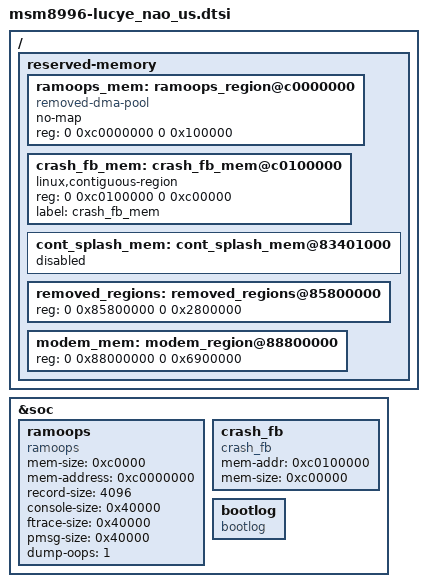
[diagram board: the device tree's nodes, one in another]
/* Copyright (c) 2015, The Linux Foundation. All rights reserved.
 * Copyright (c) 2017, The LineageOS Project. All rights reserved.
 *
 * This program is free software; you can redistribute it and/or modify
 * it under the terms of the GNU General Public License version 2 and
 * only version 2 as published by the Free Software Foundation.
 *
 * This program is distributed in the hope that it will be useful,
 * but WITHOUT ANY WARRANTY; without even the implied warranty of
 * MERCHANTABILITY or FITNESS FOR A PARTICULAR PURPOSE.  See the
 * GNU General Public License for more details.
 */

/* Generic Qualcomm tree */
 #include "../../qcom/msm8996pro-v1.1.dtsi"
 #include "../../qcom/msm-pmi8996.dtsi"
 #include "../../qcom/msm8996-mtp.dtsi"

/* Device specific tree */
#include "msm8996-lucye_nao_us-panel.dtsi"
#include "../msm8996-lucye-touch-sic-sw49408.dtsi"
#include "msm8996-lucye_nao_us-usb.dtsi"

/ {
	reserved-memory {
		ramoops_mem: ramoops_region@c0000000 {
			compatible = "removed-dma-pool";
			no-map;
			reg = <0 0xc0000000 0 0x100000>;
		};

		crash_fb_mem: crash_fb_mem@c0100000 {
			linux,contiguous-region;
			reg = <0 0xc0100000 0 0xc00000>;
			label = "crash_fb_mem";
		};

		cont_splash_mem: cont_splash_mem@83401000 {
			status = "disabled";
		};

		/delete-node/ dfps_data_mem@83400000;

		removed_regions: removed_regions@85800000 {
			reg = <0 0x85800000 0 0x2800000>;
		};

		modem_mem: modem_region@88800000 {
			reg = <0 0x88000000 0 0x6900000>;
		};
	};
};

&soc {
  ramoops {
		compatible = "ramoops";
		mem-size = <0xc0000>;
		mem-address = <0xc0000000>;
		record-size = <4096>;
		console-size = <0x40000>;
		ftrace-size = <0x40000>;
		pmsg-size = <0x40000>;
		dump-oops = <1>;
	};

	crash_fb {
		compatible = "crash_fb";
		mem-addr = <0xc0100000>;
		mem-size = <0xc00000>;
	};

	bootlog {
		compatible = "bootlog";
	};
};
